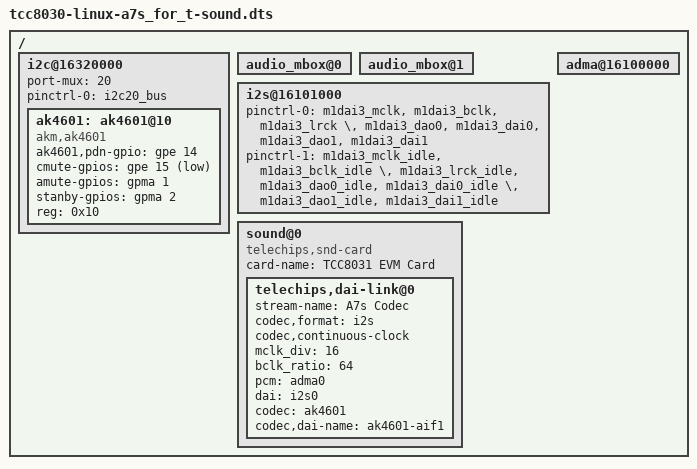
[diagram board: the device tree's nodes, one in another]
// SPDX-License-Identifier: (GPL-2.0-or-later OR MIT)
/*
 * Copyright (C) Telechips Inc.
 */

/dts-v1/;

#include "tcc8030-linux-a7s.dts"

/ {
	i2c@16320000 {
		status = "okay";
		port-mux = <20>; /* [0]SCL [1]SDA */
		pinctrl-names = "default";
		pinctrl-0 = <&i2c20_bus>;
		ak4601: ak4601@10 {
			compatible = "akm,ak4601";
			ak4601,pdn-gpio = <&gpe 14 0>;
			//CODEC_MUTE    0: active high, 1: active low
			cmute-gpios = <&gpe 15 1>;
			//AMP_MUTE      0: active high, 1: active low
			amute-gpios = <&gpma 1 0>;
			//AMP_STBY      0: active high, 1: active low
			stanby-gpios = <&gpma 2 0>;
			reg = <0x10>;
		};
	};

	audio_mbox@0 {
		status = "okay";
	};
	audio_mbox@1 {
		status = "okay";
	};

	i2s@16101000 {
		pinctrl-names = "default", "idle";
		pinctrl-0 = <&m1dai3_mclk &m1dai3_bclk &m1dai3_lrck \
			&m1dai3_dao0 &m1dai3_dai0 &m1dai3_dao1 &m1dai3_dai1>;
		pinctrl-1 = <&m1dai3_mclk_idle &m1dai3_bclk_idle \
			&m1dai3_lrck_idle &m1dai3_dao0_idle &m1dai3_dai0_idle \
			&m1dai3_dao1_idle &m1dai3_dai1_idle>;
		status = "okay";
	};

	adma@16100000 {
		status = "okay";
	};

	sound@0 {
		compatible = "telechips,snd-card";
		card-name = "TCC8031 EVM Card";
		status = "okay";

		telechips,dai-link@0 {
			stream-name="A7s Codec";
			codec,format = "i2s"; // i2s, left_j, right_j
			codec,continuous-clock;
			mclk_div = <16>; // 4,6,8,16
			bclk_ratio = <64>; // 32,48,64fs
			pcm = <&adma0>;
			dai = <&i2s0>;
			codec = <&ak4601>;
			codec,dai-name = "ak4601-aif1";
		};
	};
};
